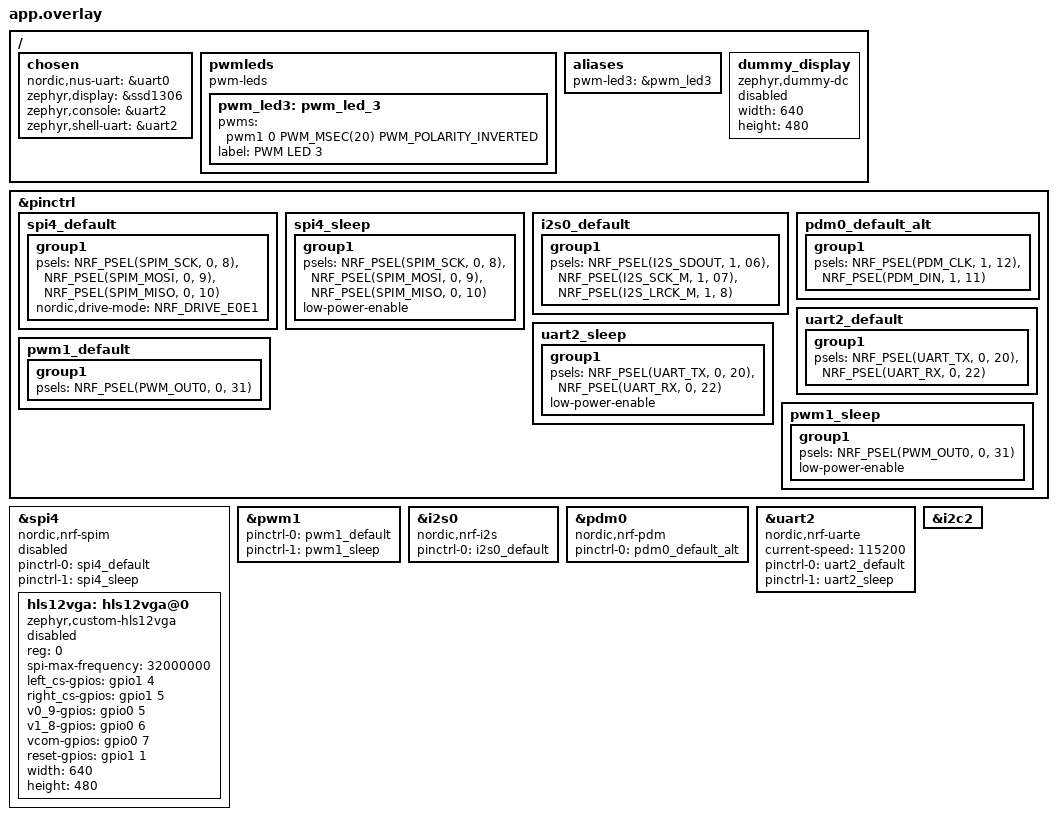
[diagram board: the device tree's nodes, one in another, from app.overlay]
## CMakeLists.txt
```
#
# Copyright (c) 2018 Nordic Semiconductor
#
# SPDX-License-Identifier: LicenseRef-Nordic-5-Clause

cmake_minimum_required(VERSION 3.20.0)

# Note: custom driver module registration enabled for HLS12VGA integration
set(ZEPHYR_EXTRA_MODULES ${CMAKE_CURRENT_SOURCE_DIR}/custom_driver_module)

find_package(Zephyr REQUIRED HINTS $ENV{ZEPHYR_BASE})
project(nrf5340_ble_simulator)

# Add nanopb support for protobuf
list(APPEND CMAKE_MODULE_PATH ${ZEPHYR_BASE}/modules/nanopb)
include(nanopb)

# Custom driver module picked up via ZEPHYR_EXTRA_MODULES (module.yml)
add_subdirectory(src/mos_components/mos_pdm)
add_subdirectory(src/mos_components/mos_interrupt)
add_subdirectory(src/mos_driver)

target_sources(app PRIVATE
    src/main.c
    src/protobuf_handler.c
    src/mentra_ble_service.c
    src/pdm_audio_stream.c
    src/lvgl_demo.c
    src/display_manager.c
    src/BspLog/bsp_log.c
    src/bsp_log_control.c
    src/shell_log_control.c
    src/shell_display_control.c
    src/shell_gx8002_control.c
    src/mos_components/mos_sysport/src/bal_os.c
    src/mos_components/mos_lvgl_display/src/mos_lvgl_display.c
    src/mos_components/mos_lvgl_display/src/display_config.c
)

# Add protobuf sources when available
if(EXISTS ${CMAKE_CURRENT_SOURCE_DIR}/src/proto/mentraos_ble.pb.c)
  target_sources(app PRIVATE src/proto/mentraos_ble.pb.c)
  target_include_directories(app PRIVATE src/proto)
elseif(EXISTS ${CMAKE_CURRENT_SOURCE_DIR}/src/mentraos_ble.pb.c)
  target_sources(app PRIVATE src/mentraos_ble.pb.c)
endif()

target_include_directories(app PRIVATE
    src
    src/BspLog
    src/mos_components/mos_sysport/include
    src/mos_components/mos_lvgl_display/include
    custom_driver_module/drivers
)
```

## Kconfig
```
#
# Copyright (c) 2018 Nordic Semiconductor
#
# SPDX-License-Identifier: LicenseRef-Nordic-5-Clause
#

source "Kconfig.zephyr"

menu "Nordic UART BLE GATT service sample"

config BT_NUS_THREAD_STACK_SIZE
	int "Thread stack size"
	default 1024
	help
	  Stack size used in each of the two threads

config BT_NUS_UART_BUFFER_SIZE
	int "UART payload buffer element size"
	default 40
	help
	  Size of the payload buffer in each RX and TX FIFO element

config BT_NUS_SECURITY_ENABLED
	bool "Enable security"
	default y
	select BT_SMP
	help
	  "Enable BLE security for the UART service"

config BT_NUS_UART_RX_WAIT_TIME
	int "Timeout for UART RX complete event"
	default 50000
	help
	  Wait for RX complete event time in microseconds

config SETTINGS
	default y

config ZMS
	default y if (SOC_FLASH_NRF_RRAM || SOC_FLASH_NRF_MRAM)

config NVS
	default y if !(SOC_FLASH_NRF_RRAM || SOC_FLASH_NRF_MRAM)

endmenu

# Include custom driver module Kconfig (projector display)
rsource "custom_driver_module/Kconfig"
```

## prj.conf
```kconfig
#
# Copyright (c) 2018 Nordic Semiconductor
#
# SPDX-License-Identifier: LicenseRef-Nordic-5-Clause
#

# Enable the UART driver
CONFIG_UART_ASYNC_API=y
CONFIG_NRFX_UARTE0=y
CONFIG_SERIAL=y

CONFIG_GPIO=y

# High-Frequency Clock Configuration for SPI Performance
CONFIG_CLOCK_CONTROL=y
CONFIG_CLOCK_CONTROL_NRF=y
# Enable NRFX clock driver for 128MHz configuration
CONFIG_NRFX_CLOCK=y
# Enable high-frequency external crystal for better SPI timing
CONFIG_SYSTEM_CLOCK_NO_WAIT=y

# Make sure printk is printing to the UART console
CONFIG_CONSOLE=y
CONFIG_UART_CONSOLE=y

CONFIG_HEAP_MEM_POOL_SIZE=2048

# High-Frequency Clock Configuration for SPI Performance
CONFIG_CLOCK_CONTROL=y
CONFIG_CLOCK_CONTROL_NRF=y
# Enable high-frequency external crystal for better SPI timing
CONFIG_SYSTEM_CLOCK_NO_WAIT=y

CONFIG_BT=y
CONFIG_BT_PERIPHERAL=y
CONFIG_BT_DEVICE_NAME="NexSim"
CONFIG_BT_MAX_CONN=1
CONFIG_BT_MAX_PAIRED=1

# Enable BLE GATT
CONFIG_BT_GATT_SERVICE_CHANGED=y

# Enable advertising
CONFIG_BT_BROADCASTER=y
CONFIG_BT_EXT_ADV=n

# Increase buffer sizes for protobuf messages
CONFIG_BT_L2CAP_TX_MTU=247
CONFIG_BT_BUF_ACL_RX_SIZE=251
CONFIG_BT_BUF_ACL_TX_SIZE=251

# Enable bonding
CONFIG_BT_SETTINGS=y
CONFIG_FLASH=y
CONFIG_FLASH_PAGE_LAYOUT=y
CONFIG_FLASH_MAP=y

# Enable DK LED and Buttons library
CONFIG_DK_LIBRARY=y

# Enable PWM for LED brightness control
CONFIG_PWM=y
CONFIG_PWM_LOG_LEVEL_DBG=y

CONFIG_SYSTEM_WORKQUEUE_STACK_SIZE=2048

CONFIG_MAIN_STACK_SIZE=4096
# Config logger
CONFIG_LOG=y
CONFIG_USE_SEGGER_RTT=y
# CONFIG_LOG_BACKEND_RTT=y
CONFIG_LOG_BACKEND_UART=n

CONFIG_LOG_PRINTK=y
# CONFIG_LOG_DEFAULT_LEVEL=0
# Configure log filtering - ensure printk goes to console
CONFIG_LOG_RUNTIME_FILTERING=y

CONFIG_ASSERT=y

# Enable nanopb for protobuf support
CONFIG_NANOPB=y

# Display + LVGL Configuration - WORKING IMPLEMENTATION FROM PERIPHERAL_UART_NEXT
CONFIG_DISPLAY=y
CONFIG_DISPLAY_LOG_LEVEL_ERR=y
CONFIG_LVGL=y
CONFIG_LV_COLOR_DEPTH_1=y
CONFIG_LV_Z_MEM_POOL_SIZE=65536
CONFIG_LV_USE_LABEL=y
CONFIG_LV_USE_THEME_DEFAULT=y

# Enable LVGL for Zephyr
CONFIG_LV_Z_FLUSH_THREAD=y
CONFIG_LV_Z_FLUSH_THREAD_STACK_SIZE=4096

# LVGL Display Buffer Settings - MUCH LARGER for full screen updates
# CONFIG_LV_Z_FULL_REFRESH=y
CONFIG_LV_Z_VDB_SIZE=40
CONFIG_LV_Z_DOUBLE_VDB=y
CONFIG_LV_Z_VDB_CUSTOM_SECTION=n
# Remove dummy display - switching to A6N projector for testing
# CONFIG_DUMMY_DISPLAY=y

# Enable custom A6N Display Driver for projector testing  
CONFIG_CUSTOM_A6N=y

# SPI Support for Display with High-Frequency Optimization
CONFIG_SPI=y
# Enhanced SPI configuration for 32MHz operation
CONFIG_SPI_ASYNC=y

# LVGL Fonts - Keep minimal set to save FLASH memory
CONFIG_LV_FONT_MONTSERRAT_12=y
CONFIG_LV_FONT_MONTSERRAT_14=y
# Large display fonts disabled to save FLASH memory
# CONFIG_LV_FONT_MONTSERRAT_16=y  
# CONFIG_LV_FONT_MONTSERRAT_18=y
# CONFIG_LV_FONT_MONTSERRAT_24=y
CONFIG_LV_FONT_MONTSERRAT_30=y
CONFIG_LV_FONT_MONTSERRAT_48=y

# Unicode and Font support for Chinese characters - minimal set
CONFIG_LV_USE_FONT_COMPRESSED=y
CONFIG_LV_FONT_FMT_TXT_LARGE=y

# Enable extended ASCII and Unicode support
CONFIG_LV_TXT_ENC_UTF8=y

# Enable only essential Chinese CJK font (14px sufficient for SSD1306)
# CONFIG_LV_FONT_SIMSUN_14_CJK=y
# CONFIG_LV_FONT_SIMSUN_16_CJK=y  # Disabled to save ~70KB

# International fonts disabled to save memory
# CONFIG_LV_FONT_DEJAVU_16_PERSIAN_HEBREW=y  # Disabled to save ~20KB  
# CONFIG_LV_FONT_UNSCII_8=y                 # Disabled to save ~8KB
# CONFIG_LV_FONT_UNSCII_16=y                # Disabled to save ~15KB

# Power Management
CONFIG_PM_DEVICE=y

# PDM Audio Configuration for Microphone Input
CONFIG_AUDIO=y
CONFIG_AUDIO_DMIC=y
CONFIG_AUDIO_DMIC_NRFX_PDM=y

# LC3 Codec Configuration for Audio Streaming  
CONFIG_AUDIO_CODEC=y

# Math library for audio processing
CONFIG_NEWLIB_LIBC=y
CONFIG_FPU=y


CONFIG_CMSIS_DSP=y
CONFIG_SW_CODEC_LC3_T2_SOFTWARE=y
CONFIG_LC3_ENC_CHAN_MAX=2
CONFIG_LC3_DEC_CHAN_MAX=2

CONFIG_NRFX_I2S0=y
CONFIG_USER_STEREO_1RX_L_1RX_R=y
# CONFIG_USER_STEREO_2RX_L is not set
# CONFIG_USER_STEREO_2RX_LR is not set

CONFIG_BT_USER_PHY_UPDATE=y
CONFIG_BT_USER_DATA_LEN_UPDATE=y

# CONFIG_SEGGER_RTT_BUFFER_SIZE_UP=4096
CONFIG_LOG_BUFFER_SIZE=8192
CONFIG_LOG_MODE_IMMEDIATE=n 
CONFIG_LOG_MODE_DEFERRED=y



CONFIG_SSD1306=y
CONFIG_I2C=y
# Additional I2C and SSD1306 support
CONFIG_GPIO=y
CONFIG_DISPLAY_LOG_LEVEL_DBG=y

CONFIG_TFM_SECURE_UART=n
CONFIG_TFM_LOG_LEVEL_SILENCE=y

# CONFIG_LV_USE_SYSMON=y
# CONFIG_LV_USE_PERF_MONITOR=y
# CONFIG_LV_FONT_DEFAULT_MONTSERRAT_12=y
# CONFIG_LV_USE_PERF_MONITOR_LOG_MODE=y

CONFIG_SHELL=y
CONFIG_LOG_CMDS=y
CONFIG_SHELL_BACKEND_SERIAL=y
CONFIG_SHELL_BACKEND_RTT=y
CONFIG_SHELL_PROMPT_UART="nrf5340:~$ "
CONFIG_SHELL_PROMPT_RTT="nrf5340:~$ "
CONFIG_SHELL_CMD_BUFF_SIZE=256
CONFIG_SHELL_PRINTF_BUFF_SIZE=64
CONFIG_SHELL_BACKEND_SERIAL_TX_RING_BUFFER_SIZE=512
CONFIG_SHELL_STACK_SIZE=8192
CONFIG_SHELL_BACKEND_SERIAL_LOG_MESSAGE_QUEUE_SIZE=2048
CONFIG_I2C_SHELL=y
CONFIG_SENSOR_SHELL=y

CONFIG_REGULATOR=y
CONFIG_SENSOR=y
CONFIG_LED=y
CONFIG_NRF_FUEL_GAUGE=y
CONFIG_NRF_FUEL_GAUGE_VARIANT_SECONDARY_CELL=y
# CONFIG_LSM6DSV16X=y
# CONFIG_LIS2MDL=y
```

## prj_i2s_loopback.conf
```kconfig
# I2S Simple Loopback Configuration
# This configuration enables only what's needed for I2S loopback testing

# Enable I2S
CONFIG_I2S=n
# We'll use nrfx_i2s directly, so disable Zephyr I2S driver

# Enable nrfx drivers
CONFIG_NRFX=y
CONFIG_NRFX_I2S=y
CONFIG_NRFX_CLOCK=y

# Enable GPIO for LED status
CONFIG_GPIO=y

# Enable logging
CONFIG_LOG=y
CONFIG_LOG_DEFAULT_LEVEL=3
CONFIG_USE_SEGGER_RTT=y
CONFIG_LOG_BACKEND_RTT=y
CONFIG_LOG_BACKEND_UART=n

# Enable console for logging
CONFIG_CONSOLE=y
CONFIG_RTT_CONSOLE=y
CONFIG_UART_CONSOLE=n

# System configuration
CONFIG_MAIN_STACK_SIZE=4096
CONFIG_SYSTEM_WORKQUEUE_STACK_SIZE=2048

# Memory configuration
CONFIG_HEAP_MEM_POOL_SIZE=8192

# Enable device tree overlays
CONFIG_PINCTRL=y

# Disable unused subsystems to avoid conflicts
CONFIG_BT=n
CONFIG_USB_DEVICE_STACK=n
CONFIG_NETWORKING=n
CONFIG_WIFI=n

# Enable floating point for audio processing if needed
CONFIG_FPU=y
CONFIG_CBPRINTF_FP_SUPPORT=y
```

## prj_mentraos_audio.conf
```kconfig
# MentraOS Audio System Configuration
# Enables PDM microphone and I2S audio output for complete audio pipeline

# Core system configuration
CONFIG_MAIN_STACK_SIZE=4096
CONFIG_SYSTEM_WORKQUEUE_STACK_SIZE=2048

# Audio subsystem
CONFIG_AUDIO=y

# I2S Audio Output Driver
CONFIG_I2S=y
CONFIG_NRFX_I2S=y
CONFIG_NRFX_I2S0=y

# PDM Microphone Driver  
CONFIG_PDM=y
CONFIG_NRFX_PDM=y
CONFIG_NRFX_PDM0=y

# GPIO for status indication
CONFIG_GPIO=y

# Audio clock configuration
CONFIG_CLOCK_CONTROL=y
CONFIG_NRFX_CLOCK=y
CONFIG_CLOCK_CONTROL_NRF_K32SRC_XTAL=y
CONFIG_CLOCK_CONTROL_NRF_K32SRC_500PPM=y

# High frequency clock for audio precision
CONFIG_CLOCK_CONTROL_NRF_HFCLK_DIV=1

# Audio clock (ACLK) for I2S and PDM
CONFIG_NRFX_CLOCK_LFCLK_RC=y

# Memory management for audio buffers
CONFIG_HEAP_MEM_POOL_SIZE=8192
CONFIG_SLAB_ALLOC=y

# Logging configuration for debugging
CONFIG_LOG=y
CONFIG_LOG_DEFAULT_LEVEL=3
CONFIG_LOG_BACKEND_UART=y
CONFIG_LOG_MODE_IMMEDIATE=y
CONFIG_CONSOLE=y
CONFIG_UART_CONSOLE=y
CONFIG_SERIAL=y

# Thread and synchronization
CONFIG_MULTITHREADING=y
CONFIG_NUM_COOP_PRIORITIES=10
CONFIG_NUM_PREEMPT_PRIORITIES=15
CONFIG_THREAD_NAME=y
CONFIG_THREAD_STACK_INFO=y

# Ring buffer for audio data flow
CONFIG_RING_BUFFER=y

# Math library for audio processing
CONFIG_NEWLIB_LIBC=y
CONFIG_NEWLIB_LIBC_FLOAT_PRINTF=y

# Power management (can be disabled for debug)
CONFIG_PM=n

# Networking disabled for audio focus
CONFIG_NETWORKING=n
CONFIG_BT=n

# USB for development (optional)
CONFIG_USB_DEVICE_STACK=y
CONFIG_USB_CDC_ACM=y

# Debug features
CONFIG_DEBUG=y
CONFIG_DEBUG_OPTIMIZATIONS=y
CONFIG_ASSERT=y
CONFIG_ASSERT_LEVEL=2

# Performance monitoring
CONFIG_TIMING_FUNCTIONS=y
CONFIG_THREAD_RUNTIME_STATS=y

# Pin control configuration
CONFIG_PINCTRL=y

# Device tree overlay
CONFIG_DTC_OVERLAY_FILE="mentraos_audio.overlay"
```

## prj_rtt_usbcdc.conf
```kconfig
# Combined Configuration: RTT Shell Backend + USB CDC Shell Backend
# Based on our RTT implementation + Cole's USB CDC implementation from dev-nexfirmware-a6n

# RTT Shell Backend Configuration - Real-time debugging via J-Link RTT
CONFIG_USE_SEGGER_RTT=y
CONFIG_SHELL_BACKEND_RTT=y
CONFIG_RTT_CONSOLE=y
CONFIG_SEGGER_RTT_MAX_NUM_UP_BUFFERS=3
CONFIG_SEGGER_RTT_MAX_NUM_DOWN_BUFFERS=3
CONFIG_SEGGER_RTT_BUFFER_SIZE_UP=1024
CONFIG_SEGGER_RTT_BUFFER_SIZE_DOWN=16
CONFIG_SEGGER_RTT_PRINTF_BUFFER_SIZE=64

# Shell Prompt Configuration - Unified MentraOS branding
CONFIG_SHELL_PROMPT_UART="MentraOS:~$ "
CONFIG_SHELL_PROMPT_RTT="MentraOS:~$ "

# USB CDC ACM Configuration for Shell and Log via USB
# Based on Cole's implementation from dev-nexfirmware-a6n branch
CONFIG_USB_DEVICE_STACK=y
CONFIG_USB_DEVICE_MANUFACTURER="Nordic Semiconductor"
CONFIG_USB_DEVICE_PRODUCT="nRF5340 BLE Simulator"
CONFIG_USB_DEVICE_VID=0x1915
CONFIG_USB_DEVICE_PID=0x530A
CONFIG_USB_CDC_ACM=y
CONFIG_UART_LINE_CTRL=y
CONFIG_USB_DEVICE_INITIALIZE_AT_BOOT=y
```

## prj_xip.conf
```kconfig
#
# XIP (eXecute In Place) Configuration for External SPI NOR Flash
# Based on prj.conf with XIP-specific additions
#

# Include base configuration
include prj.conf

# External Flash Support
CONFIG_NORDIC_QSPI_NOR=y
CONFIG_NORDIC_QSPI_NOR_FLASH_LAYOUT_PAGE_SIZE=4096
CONFIG_NORDIC_QSPI_NOR_STACK_WRITE_BUFFER_SIZE=16

# XIP (eXecute In Place) Configuration
CONFIG_XIP=y
CONFIG_MAIN_STACK_SIZE=4096
CONFIG_SYSTEM_WORKQUEUE_STACK_SIZE=4096

# Flash Configuration for XIP
CONFIG_FLASH=y
CONFIG_FLASH_PAGE_LAYOUT=y
CONFIG_FLASH_MAP=y
CONFIG_STREAM_FLASH=y

# LittleFS Configuration for External Flash
CONFIG_FILE_SYSTEM=y
CONFIG_FILE_SYSTEM_LITTLEFS=y
CONFIG_LITTLEFS_READ_SIZE=16
CONFIG_LITTLEFS_PROG_SIZE=16
CONFIG_LITTLEFS_CACHE_SIZE=64
CONFIG_LITTLEFS_LOOKAHEAD_SIZE=16
CONFIG_LITTLEFS_BLOCK_SIZE=4096
CONFIG_LITTLEFS_USE_MTIME=y

# Memory Management for XIP
CONFIG_HEAP_MEM_POOL_SIZE=8192
CONFIG_MAIN_STACK_SIZE=4096

# QSPI Performance Optimization
CONFIG_NORDIC_QSPI_NOR_FLASH_LAYOUT_PAGE_SIZE=4096
CONFIG_NORDIC_QSPI_NOR_STACK_WRITE_BUFFER_SIZE=16

# Enable XIP debugging
CONFIG_XIP_DEBUG=y
CONFIG_FLASH_LOG_LEVEL_DBG=y

# Bootloader Configuration for XIP
CONFIG_BOOTLOADER_MCUBOOT=y
CONFIG_IMG_MANAGER=y
CONFIG_IMG_ERASE_PROGRESSIVELY=y

# Partition Manager for XIP
CONFIG_PM_PARTITION_SIZE_MCUBOOT=0x10000
CONFIG_PM_PARTITION_SIZE_XIP=0x400000
CONFIG_PM_PARTITION_SIZE_LITTLEFS_STORAGE=0x400000
```

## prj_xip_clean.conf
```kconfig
# XIP Configuration Overlay for MX25R6435F 8MB NOR Flash  
# This file works with prj.conf to enable XIP functionality
# Usage: west build -- -DCONF_FILE="prj.conf;prj_xip_clean.conf"

# Core XIP Configuration
CONFIG_XIP=y

# Custom linker script for XIP support
CONFIG_HAVE_CUSTOM_LINKER_SCRIPT=y
CONFIG_CUSTOM_LINKER_SCRIPT="linker_arm_extxip.ld"

# External Flash Support via QSPI
CONFIG_FLASH=y
CONFIG_FLASH_MAP=y
CONFIG_FLASH_PAGE_LAYOUT=y
CONFIG_NORDIC_QSPI_NOR=y
CONFIG_NORDIC_QSPI_NOR_FLASH_LAYOUT_PAGE_SIZE=4096
CONFIG_NORDIC_QSPI_NOR_XIP=y

# File System Support
CONFIG_FILE_SYSTEM=y
CONFIG_FILE_SYSTEM_LITTLEFS=y

# Shell support for XIP testing  
CONFIG_SHELL=y
CONFIG_SHELL_BACKEND_SERIAL=y
CONFIG_SHELL_PROMPT_UART="xip:~$ "

# Enable additional logging for XIP debugging
CONFIG_LOG=y
CONFIG_LOG_DEFAULT_LEVEL=3
CONFIG_FLASH_LOG_LEVEL_DBG=y

# Memory optimization for XIP
CONFIG_MAIN_STACK_SIZE=4096
CONFIG_SYSTEM_WORKQUEUE_STACK_SIZE=4096

# Disable HLS12VGA driver for XIP testing to avoid undefined references
CONFIG_CUSTOM_HLS12VGA=n
```

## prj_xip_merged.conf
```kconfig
#
# Merged XIP Configuration for External SPI NOR Flash
# Based on prj.conf with XIP-specific additions
#

# Enable the UART driver
CONFIG_UART_ASYNC_API=y
CONFIG_NRFX_UARTE0=y
CONFIG_SERIAL=y

CONFIG_GPIO=y

# High-Frequency Clock Configuration for SPI Performance
CONFIG_CLOCK_CONTROL=y
CONFIG_CLOCK_CONTROL_NRF=y
# Enable NRFX clock driver for 128MHz configuration
CONFIG_NRFX_CLOCK=y
# Enable high-frequency external crystal for better SPI timing
CONFIG_SYSTEM_CLOCK_NO_WAIT=y

# Make sure printk is printing to the UART console
CONFIG_CONSOLE=y
CONFIG_UART_CONSOLE=y

CONFIG_HEAP_MEM_POOL_SIZE=8192

CONFIG_BT=y
CONFIG_BT_PERIPHERAL=y
CONFIG_BT_DEVICE_NAME="NexSim"
CONFIG_BT_MAX_CONN=1
CONFIG_BT_MAX_PAIRED=1

# Enable BLE GATT
CONFIG_BT_GATT_SERVICE_CHANGED=y

# Enable advertising
CONFIG_BT_BROADCASTER=y
CONFIG_BT_EXT_ADV=n

# Increase buffer sizes for protobuf messages
CONFIG_BT_L2CAP_TX_MTU=247
CONFIG_BT_BUF_ACL_RX_SIZE=251
CONFIG_BT_BUF_ACL_TX_SIZE=251

# Enable BT data length update
CONFIG_BT_DATA_LEN_UPDATE=y
CONFIG_BT_AUTO_DATA_LEN_UPDATE=y

# Enable BT PHY update
CONFIG_BT_PHY_UPDATE=y
CONFIG_BT_AUTO_PHY_UPDATE=y

# Enable DMIC/PDM for digital microphone input
CONFIG_AUDIO=y
CONFIG_AUDIO_DMIC=y

# Additional display/audio configurations from base prj.conf
CONFIG_DISPLAY=y
CONFIG_LVGL=y
CONFIG_LV_COLOR_DEPTH_1=y
CONFIG_LV_MEM_CUSTOM=y
CONFIG_LV_USE_LOG=y
CONFIG_LV_LOG_LEVEL_WARN=y
CONFIG_LV_THEME_BASIC=y
CONFIG_LV_USE_THEME_BASIC=y
CONFIG_LV_THEME_DEFAULT_DARK=y
CONFIG_LV_COLOR_CHROMA_KEY_HEX=0x00FF00

# Enable custom HLS12VGA Display Driver for projector testing  
CONFIG_CUSTOM_HLS12VGA=y

# SPI Support for Display with High-Frequency Optimization
CONFIG_SPI=y
CONFIG_SPI_ASYNC=y

# LVGL Fonts - Keep minimal set to save FLASH memory
CONFIG_LV_FONT_MONTSERRAT_12=y
CONFIG_LV_FONT_MONTSERRAT_14=y

# Unicode and Font support
CONFIG_LV_USE_FONT_COMPRESSED=y
CONFIG_LV_FONT_FMT_TXT_LARGE=y
CONFIG_LV_TXT_ENC_UTF8=y
CONFIG_LV_FONT_SIMSUN_14_CJK=y

# Power Management
CONFIG_PM_DEVICE=y

# PDM Audio Configuration for Microphone Input
CONFIG_AUDIO_DMIC_NRFX_PDM=y

# LC3 Codec Configuration for Audio Streaming  
CONFIG_AUDIO_CODEC=y

# Math library for audio processing
CONFIG_NEWLIB_LIBC=y
CONFIG_FPU=y
CONFIG_CMSIS_DSP=y
CONFIG_SW_CODEC_LC3_T2_SOFTWARE=y
CONFIG_LC3_ENC_CHAN_MAX=2
CONFIG_LC3_DEC_CHAN_MAX=2

CONFIG_NRFX_I2S0=y
CONFIG_USER_STEREO_1RX_L_1RX_R=y

CONFIG_BT_USER_PHY_UPDATE=y
CONFIG_BT_USER_DATA_LEN_UPDATE=y

# XIP-specific configurations
CONFIG_SEGGER_RTT_BUFFER_SIZE_UP=4096
CONFIG_CBPRINTF_FP_SUPPORT=y
CONFIG_MAIN_STACK_SIZE=4096
CONFIG_RTT_CONSOLE=y

# Logging configurations
CONFIG_LOG_BUFFER_SIZE=8192
CONFIG_LOG_MODE_IMMEDIATE=n 
CONFIG_LOG_MODE_DEFERRED=y

# Display configurations
CONFIG_SSD1306=y
CONFIG_I2C=y
CONFIG_DISPLAY_LOG_LEVEL_DBG=y

CONFIG_TFM_SECURE_UART=n
CONFIG_TFM_LOG_LEVEL_SILENCE=y

# Shell configurations - essential for XIP shell commands
CONFIG_SHELL=y
CONFIG_LOG_CMDS=y
CONFIG_SHELL_BACKEND_SERIAL=y
CONFIG_SHELL_PROMPT_UART="nrf5340:~$ "
CONFIG_SHELL_CMD_BUFF_SIZE=256
CONFIG_SHELL_PRINTF_BUFF_SIZE=64
CONFIG_SHELL_BACKEND_SERIAL_TX_RING_BUFFER_SIZE=4096
CONFIG_SHELL_STACK_SIZE=8192

# External Flash Support for XIP
CONFIG_NORDIC_QSPI_NOR=y
CONFIG_NORDIC_QSPI_NOR_FLASH_LAYOUT_PAGE_SIZE=4096
CONFIG_NORDIC_QSPI_NOR_STACK_WRITE_BUFFER_SIZE=16

# XIP (eXecute In Place) Configuration
CONFIG_XIP=y
CONFIG_SYSTEM_WORKQUEUE_STACK_SIZE=4096

# Flash Configuration for XIP
CONFIG_FLASH=y
CONFIG_FLASH_PAGE_LAYOUT=y
CONFIG_FLASH_MAP=y
CONFIG_STREAM_FLASH=y

# LittleFS Configuration for External Flash
CONFIG_FILE_SYSTEM=y
CONFIG_FILE_SYSTEM_LITTLEFS=y

# Enable QSPI Performance Optimization
CONFIG_NORDIC_QSPI_NOR_FLASH_LAYOUT_PAGE_SIZE=4096
CONFIG_NORDIC_QSPI_NOR_STACK_WRITE_BUFFER_SIZE=16

# Bootloader Configuration for XIP
CONFIG_BOOTLOADER_MCUBOOT=y
CONFIG_IMG_MANAGER=y
CONFIG_IMG_ERASE_PROGRESSIVELY=y
```

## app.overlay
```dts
/*
 * Copyright (c) 2022 Nordic Semiconductor ASA
 *
 * SPDX-License-Identifier: LicenseRef-Nordic-5-Clause
 */

/ {
	chosen {
		nordic,nus-uart = &uart0;
		/* Use HLS12VGA projector display */
		// zephyr,display = &hls12vga;
		zephyr,display = &ssd1306;
		/* UART2 for console/shell output on P0.20 (TX) and P0.22 (RX) */
		zephyr,console = &uart2;
		zephyr,shell-uart = &uart2;
	};
	
	pwmleds {
		compatible = "pwm-leds";
		
		/* PWM LED for brightness control on LED 3 (P0.31) */
		pwm_led3: pwm_led_3 {
			pwms = <&pwm1 0 PWM_MSEC(20) PWM_POLARITY_INVERTED>;
			label = "PWM LED 3";
		};
	};
	
	aliases {
		pwm-led3 = &pwm_led3;
	};

	/* Dummy display for testing (until projector driver properly integrated) */
	dummy_display: dummy_display {
		compatible = "zephyr,dummy-dc";
		width = <640>;
		height = <480>;
		status = "disabled";  // Disabled since we're using SSD1306
	};
};

&pinctrl {
	spi4_default: spi4_default {
		group1 {
			psels = <NRF_PSEL(SPIM_SCK,  0, 8)>,
			        <NRF_PSEL(SPIM_MOSI, 0, 9)>,
			        <NRF_PSEL(SPIM_MISO, 0, 10)>;
			nordic,drive-mode = <NRF_DRIVE_E0E1>;
		};
	};
	spi4_sleep: spi4_sleep {
		group1 {
			psels = <NRF_PSEL(SPIM_SCK,  0, 8)>,
			        <NRF_PSEL(SPIM_MOSI, 0, 9)>,
			        <NRF_PSEL(SPIM_MISO, 0, 10)>;
			low-power-enable;
		};
	};
	i2s0_default: i2s0_default {
		group1 {
			psels = <NRF_PSEL(I2S_SDOUT, 1, 06)>,
					<NRF_PSEL(I2S_SCK_M, 1, 07)>,
					<NRF_PSEL(I2S_LRCK_M, 1, 8)>;
			// <NRF_PSEL(I2S_SDIN, 0, 0)>;

		};
	};
	pdm0_default_alt: pdm0_default_alt {
		group1 {
			psels = <NRF_PSEL(PDM_CLK, 1, 12)>,
					<NRF_PSEL(PDM_DIN, 1, 11)>;

		};
	};

	// UART2 pinctrl configuration for P0.20 (TX) and P0.22 (RX)
	uart2_default: uart2_default {
		group1 {
			psels = <NRF_PSEL(UART_TX, 0, 20)>,
					<NRF_PSEL(UART_RX, 0, 22)>;
		};
	};
	uart2_sleep: uart2_sleep {
		group1 {
			psels = <NRF_PSEL(UART_TX, 0, 20)>,
					<NRF_PSEL(UART_RX, 0, 22)>;
			low-power-enable;
		};
	};

	// I2C2 pinctrl moved to board overlay
};

&spi4 {
	compatible = "nordic,nrf-spim";
	status = "disabled";
	pinctrl-0 = <&spi4_default>;
	pinctrl-1 = <&spi4_sleep>;
	pinctrl-names = "default", "sleep";

	hls12vga: hls12vga@0 {
		compatible = "zephyr,custom-hls12vga";
		reg = <0>;
		status = "disabled";
		spi-max-frequency = <32000000>;

		left_cs-gpios  = <&gpio1 4 GPIO_ACTIVE_HIGH>;
		right_cs-gpios = <&gpio1 5 GPIO_ACTIVE_HIGH>;
		v0_9-gpios     = <&gpio0 5 GPIO_ACTIVE_HIGH>;
		v1_8-gpios     = <&gpio0 6 GPIO_ACTIVE_HIGH>;
		vcom-gpios     = <&gpio0 7 GPIO_ACTIVE_HIGH>;
		reset-gpios    = <&gpio1 1 GPIO_ACTIVE_HIGH>;
		width = <640>;
		height = <480>;
	};
};

&pinctrl {
	pwm1_default: pwm1_default {
		group1 {
			psels = <NRF_PSEL(PWM_OUT0, 0, 31)>;
		};
	};

	pwm1_sleep: pwm1_sleep {
		group1 {
			psels = <NRF_PSEL(PWM_OUT0, 0, 31)>;
			low-power-enable;
		};
	};
};

&pwm1 {
	status = "okay";
	pinctrl-0 = <&pwm1_default>;
	pinctrl-1 = <&pwm1_sleep>;
	pinctrl-names = "default", "sleep";
};

&i2s0 {
	compatible = "nordic,nrf-i2s";
	status = "okay";
	pinctrl-0 = <&i2s0_default>;
	pinctrl-names = "default";
	// clock-source = "ACLK";
};

dmic_dev: &pdm0 {
	status = "okay";
	compatible = "nordic,nrf-pdm";
	pinctrl-0 = <&pdm0_default_alt>;
	pinctrl-names = "default";
	// clock-source = "ACLK";
};

// Enable UART2 for console/shell on P0.20 (TX) and P0.22 (RX)
&uart2 {
	compatible = "nordic,nrf-uarte";
	status = "okay";
	current-speed = <115200>;
	pinctrl-0 = <&uart2_default>;
	pinctrl-1 = <&uart2_sleep>;
	pinctrl-names = "default", "sleep";
};

&i2c2 {
    // SSD1306 configuration moved to board overlay
};
```

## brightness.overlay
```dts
/*
 * Copyright (c) 2024 Mentra
 *
 * SPDX-License-Identifier: Apache-2.0
 */

/ {
	pwmleds {
		compatible = "pwm-leds";
		
		/* PWM LED for brightness control on LED 3 (P0.31) */
		pwm_led3: pwm_led_3 {
			pwms = <&pwm1 0 PWM_MSEC(20) PWM_POLARITY_INVERTED>;
			label = "PWM LED 3";
		};
	};
	
	aliases {
		pwm-led3 = &pwm_led3;
	};
};

&pinctrl {
	pwm1_default: pwm1_default {
		group1 {
			psels = <NRF_PSEL(PWM_OUT0, 0, 31)>;
		};
	};

	pwm1_sleep: pwm1_sleep {
		group1 {
			psels = <NRF_PSEL(PWM_OUT0, 0, 31)>;
			low-power-enable;
		};
	};
};

&pwm1 {
	status = "okay";
	pinctrl-0 = <&pwm1_default>;
	pinctrl-1 = <&pwm1_sleep>;
	pinctrl-names = "default", "sleep";
};
```

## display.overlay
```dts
/*
 * Simplified Display Configuration for LVGL Testing
 * Uses dummy display driver to test LVGL functionality
 */

/ {
	chosen {
		zephyr,display = &dummy_display;
	};

	/* Dummy display device for LVGL testing */
	dummy_display: dummy_display {
		compatible = "zephyr,dummy-display";
		status = "okay";
		width = <640>;
		height = <480>;
		refresh-time-ms = <16>;  /* ~60 FPS */
	};
};
```

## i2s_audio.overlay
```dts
/**
 * I2S Audio Output Device Tree Overlay
 * 
 * Configures I2S peripheral for audio output on nRF5340DK
 * 
 * Pin Mapping:
 * - P1.06: I2S_LRCK (Left/Right Clock)
 * - P1.07: I2S_BCLK (Bit Clock)  
 * - P1.08: I2S_SDIN (Serial Data Input to DAC)
 * 
 * Audio Configuration:
 * - Sample Rate: 16kHz
 * - Channels: Stereo (2)
 * - Bit Depth: 16-bit
 * - Frame Duration: 10ms
 */

&pinctrl {
	i2s0_default: i2s0_default {
		group1 {
			/* I2S Clock signals */
			psels = <NRF_PSEL(I2S_LRCK, 1, 6)>,   /* P1.06 - Left/Right Clock */
			        <NRF_PSEL(I2S_BCLK, 1, 7)>,   /* P1.07 - Bit Clock */
			        <NRF_PSEL(I2S_SDIN, 1, 8)>;   /* P1.08 - Serial Data Input */
		};
	};

	i2s0_sleep: i2s0_sleep {
		group1 {
			psels = <NRF_PSEL(I2S_LRCK, 1, 6)>,
			        <NRF_PSEL(I2S_BCLK, 1, 7)>,
			        <NRF_PSEL(I2S_SDIN, 1, 8)>;
			low-power-enable;
		};
	};
};

&i2s0 {
	status = "okay";
	pinctrl-0 = <&i2s0_default>;
	pinctrl-1 = <&i2s0_sleep>;
	pinctrl-names = "default", "sleep";
	
	/* I2S Master Configuration */
	clock-source = "HFCLK";  /* High frequency clock for precision */
	
	/* Audio format configuration */
	master;                  /* nRF5340 is I2S master */
};
```

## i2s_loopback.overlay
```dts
/*
 * I2S Simple Loopback Device Tree Overlay
 * Configures I2S pins for nRF5340DK
 */

&pinctrl {
    i2s0_default: i2s0_default {
        group1 {
            psels = <NRF_PSEL(I2S_SCK_M, 1, 7)>,    /* P1.07 - BCLK */
                    <NRF_PSEL(I2S_LRCK_M, 1, 6)>,   /* P1.06 - LRCK */
                    <NRF_PSEL(I2S_SDOUT, 1, 8)>;    /* P1.08 - SDOUT */
        };
        group2 {
            psels = <NRF_PSEL(I2S_SDIN, 1, 9)>;     /* P1.09 - SDIN */
            bias-pull-up;
        };
    };

    i2s0_sleep: i2s0_sleep {
        group1 {
            psels = <NRF_PSEL(I2S_SCK_M, 1, 7)>,
                    <NRF_PSEL(I2S_LRCK_M, 1, 6)>,
                    <NRF_PSEL(I2S_SDOUT, 1, 8)>,
                    <NRF_PSEL(I2S_SDIN, 1, 9)>;
            low-power-enable;
        };
    };
};

&i2s0 {
    status = "disabled";  /* Disable Zephyr I2S driver to avoid conflicts */
};

/* Enable HFCLKAUDIO for audio applications */
&clock {
    hfclkaudio-frequency = <12288000>;  /* 12.288 MHz for audio */
};
```

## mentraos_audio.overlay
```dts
/**
 * @file mentraos_audio.overlay
 * @brief MentraOS Audio System Device Tree Overlay
 * 
 * Configures nRF5340 for complete audio pipeline:
 * - PDM microphone input (P1.11/P1.12)
 * - I2S audio output for MAX98357A (P1.06/P1.07/P1.08)
 * 
 * Based on actual MentraOS configuration from:
 * /Users/loayyari/Documents/Github/MentraOS_TESTS/mcu_client/nrf5340/mentraos_nrf5340/app.overlay
 * 
 * Hardware Setup:
 * MAX98357A I2S Audio Amplifier:
 *   - P1.06 → LRC (Left/Right Clock)
 *   - P1.07 → BCLK (Bit Clock)  
 *   - P1.08 → DIN (Audio Data Input)
 *   - VDD → 3.3V
 *   - GND → Ground
 * 
 * PDM Microphone:
 *   - P1.12 → CLK (PDM Clock)
 *   - P1.11 → DAT (PDM Data)
 *   - VDD → 3.3V
 *   - GND → Ground
 */

/ {
	chosen {
		// Use UART for logging output
		zephyr,console = &uart0;
		zephyr,shell-uart = &uart0;
	};
	
	aliases {
		// Define audio device aliases
		audio-i2s = &i2s0;
		audio-pdm = &pdm0;
	};
};

// Add audio clock support
&clock {
	hfclkaudio-frequency = <12288000>;
};

&pinctrl {
	// I2S pin configuration (matching MentraOS)
	i2s0_default: i2s0_default {
		group1 {
			psels = <NRF_PSEL(I2S_SDOUT, 1, 6)>,    // P1.06 - Serial Data Output to MAX98357A DIN
			        <NRF_PSEL(I2S_SCK_M, 1, 7)>,    // P1.07 - Serial Clock Master to MAX98357A BCLK
			        <NRF_PSEL(I2S_LRCK_M, 1, 8)>;   // P1.08 - LR Clock Master to MAX98357A LRC
		};
	};

	i2s0_sleep: i2s0_sleep {
		group1 {
			psels = <NRF_PSEL(I2S_SDOUT, 1, 6)>,
			        <NRF_PSEL(I2S_SCK_M, 1, 7)>,
			        <NRF_PSEL(I2S_LRCK_M, 1, 8)>;
			low-power-enable;
		};
	};

	// PDM pin configuration (matching MentraOS)
	pdm0_default_alt: pdm0_default_alt {
		group1 {
			psels = <NRF_PSEL(PDM_CLK, 1, 12)>,    // P1.12 - PDM Clock
			        <NRF_PSEL(PDM_DIN, 1, 11)>;    // P1.11 - PDM Data Input
		};
	};

	pdm0_sleep: pdm0_sleep {
		group1 {
			psels = <NRF_PSEL(PDM_CLK, 1, 12)>,
			        <NRF_PSEL(PDM_DIN, 1, 11)>;
			low-power-enable;
		};
	};
};

// I2S Audio Output Configuration (for MAX98357A)
&i2s0 {
	compatible = "nordic,nrf-i2s";
	status = "okay";
	pinctrl-0 = <&i2s0_default>;
	pinctrl-1 = <&i2s0_sleep>;
	pinctrl-names = "default", "sleep";
	
	// Audio clock configuration (matching MentraOS)
	clock-source = "ACLK";  // Use Audio Clock for precision timing
};

// PDM Microphone Configuration
&pdm0 {
	compatible = "nordic,nrf-pdm";
	status = "okay";
	pinctrl-0 = <&pdm0_default_alt>;
	pinctrl-1 = <&pdm0_sleep>;
	pinctrl-names = "default", "sleep";
	
	// PDM clock configuration - using ACLK for precision
	clock-source = "ACLK";
};

// UART Configuration for logging
&uart0 {
	status = "okay";
	current-speed = <115200>;
	pinctrl-0 = <&uart0_default>;
	pinctrl-1 = <&uart0_sleep>;
	pinctrl-names = "default", "sleep";
};

// GPIO Configuration (for status LED)
&gpio0 {
	status = "okay";
	sense-edge-mask = <0xffffffff>;
};

&gpio1 {
	status = "okay";
	sense-edge-mask = <0xffffffff>;
};

// Disable unused peripherals to save power
&uart1 {
	status = "disabled";
};

&spi0 {
	status = "disabled";
};

&spi1 {
	status = "disabled";
};

&spi2 {
	status = "disabled";
};

&i2c0 {
	status = "disabled";
};

&i2c1 {
	status = "disabled";
};

&pwm0 {
	status = "disabled";
};

&pwm1 {
	status = "disabled";
};

&pwm2 {
	status = "disabled";
};

// Disable NFC to free up pins
&nfct {
	status = "disabled";
};

// Keep USB CDC for development
&zephyr_udc0 {
	status = "okay";
};
```

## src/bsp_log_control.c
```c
/*
 * BSP Log Runtime Control
 * Provides runtime control over BSP logging levels
 */

#include "BspLog/bsp_log.h"
#include <zephyr/kernel.h>

// Runtime BSP log level control
// Default to level 0 (DISABLED) since BSP logs should have been migrated to Zephyr logging
int bsp_log_runtime_level = 0;

// Initialize BSP logging system
void bsp_log_init(void)
{
    // Set initial log level to disabled since BSP logging migration should be complete
    bsp_log_runtime_level = 0;
}

// Runtime level control functions
void bsp_log_set_level(int level)
{
    if (level >= 0 && level <= 5) {
        bsp_log_runtime_level = level;
    }
}

int bsp_log_get_level(void)
{
    return bsp_log_runtime_level;
}
```

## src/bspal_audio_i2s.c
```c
/*
 * @Author       : Cole
 * @Date         : 2025-08-05 18:00:04
 * @LastEditTime : 2025-08-18 09:41:37
 * @FilePath     : bspal_audio_i2s.c
 * @Description  :
 *
 *  Copyright (c) MentraOS Contributors 2025
 *  SPDX-License-Identifier: Apache-2.0
 */

#include "bspal_audio_i2s.h"

#include <nrfx_clock.h>
#include <nrfx_i2s.h>
#include <zephyr/device.h>
#include <zephyr/drivers/pinctrl.h>
#include <zephyr/kernel.h>

#include "BspLog/bsp_log.h"

#define I2S_NL DT_NODELABEL(i2s0)

#define TAG "BSPAL_I2S"
enum audio_i2s_state
{
    AUDIO_I2S_STATE_UNINIT,
    AUDIO_I2S_STATE_IDLE,
    AUDIO_I2S_STATE_STARTED,
};

static enum audio_i2s_state state = AUDIO_I2S_STATE_UNINIT;

PINCTRL_DT_DEFINE(I2S_NL);  // I2S0 pins

static nrfx_i2s_t i2s_inst = {
    .p_reg = NRF_I2S0,
    .drv_inst_idx = 0,
};
static uint32_t i2s_rx_req_buffer[2][PDM_PCM_REQ_BUFFER_SIZE];
static uint32_t i2s_tx_req_buffer[2][PDM_PCM_REQ_BUFFER_SIZE];

static nrfx_i2s_config_t cfg = {
    /* Pins are configured by pinctrl. */
    .skip_gpio_cfg = true,
    .skip_psel_cfg = true,
    .irq_priority = DT_IRQ(I2S_NL, priority),
    .mode = NRF_I2S_MODE_MASTER,
    .format = NRF_I2S_FORMAT_I2S,
    .alignment = NRF_I2S_ALIGN_LEFT,
    .sample_width = NRF_I2S_SWIDTH_16BIT,
    .channels = NRF_I2S_CHANNELS_STEREO,
    .enable_bypass = false,

    .clksrc    = NRF_I2S_CLKSRC_ACLK,    // Use audio clock
    .mck_setup = NRF_I2S_MCK_32MDIV8,    // For ACLK = ACLK/8 = 12.288M/8 = 1.536 MHz
    .ratio     = NRF_I2S_RATIO_96X,      // LRCK = 1.536M / 96 = 16 kHz precisely aligned
};

nrfx_i2s_buffers_t const i2s_req_buffer[2] = {
    {
        .p_rx_buffer = i2s_rx_req_buffer[0],
        .p_tx_buffer = i2s_tx_req_buffer[0],
        .buffer_size = PDM_PCM_REQ_BUFFER_SIZE,
    },

    {
        .p_rx_buffer = i2s_rx_req_buffer[1],
        .p_tx_buffer = i2s_tx_req_buffer[1],
        .buffer_size = PDM_PCM_REQ_BUFFER_SIZE,
    },
};

static uint32_t *volatile mp_block_to_fill = NULL;

static void i2s_buffer_req_evt_handle(nrfx_i2s_buffers_t const *p_released, uint32_t status)
{
    uint32_t err_code;
    if (!(status & NRFX_I2S_STATUS_NEXT_BUFFERS_NEEDED))  // If no next buffers 
    {
        BSP_LOGE(TAG, "i2s_buffer_req_evt_handle: No next buffers needed, status = %lu", status);
        return;
    }
    // p_released->p_rx_buffer is the completed buffer, can be released or used to fill next frame
    if (p_released->p_rx_buffer == NULL)
    {
        err_code = nrfx_i2s_next_buffers_set(&i2s_inst, &i2s_req_buffer[1]);
        mp_block_to_fill = i2s_tx_req_buffer[1];
    }
    else
    {
        err_code = nrfx_i2s_next_buffers_set(&i2s_inst, p_released);
        mp_block_to_fill = (uint32_t *)p_released->p_tx_buffer;
    }
}

void audio_i2s_start(void)
{
    __ASSERT_NO_MSG(state == AUDIO_I2S_STATE_IDLE);
    nrfx_err_t ret;
    /* Buffer size in 32-bit words */
    ret = nrfx_i2s_start(&i2s_inst, &i2s_req_buffer[0], 0);
    __ASSERT_NO_MSG(ret == NRFX_SUCCESS);

    state = AUDIO_I2S_STATE_STARTED;
}

void audio_i2s_stop(void)
{
    __ASSERT_NO_MSG(state == AUDIO_I2S_STATE_STARTED);

    nrfx_i2s_stop(&i2s_inst);

    state = AUDIO_I2S_STATE_IDLE;
}

// Custom I2S IRQ handler
static void i2s_irq_handler(const void *arg)
{
    nrfx_i2s_irq_handler();
}

void audio_i2s_init(void)
{
    __ASSERT_NO_MSG(state == AUDIO_I2S_STATE_UNINIT);

    nrfx_err_t ret;

    nrfx_clock_hfclkaudio_config_set(HFCLKAUDIO_12_288_MHZ);

    NRF_CLOCK->TASKS_HFCLKAUDIOSTART = 1;

    /* Wait for ACLK to start */
    while (NRF_CLOCK->EVENTS_HFCLKAUDIOSTARTED == 0)
    {
        k_sleep(K_MSEC(1));
    }

    ret = pinctrl_apply_state(PINCTRL_DT_DEV_CONFIG_GET(I2S_NL), PINCTRL_STATE_DEFAULT);
    __ASSERT_NO_MSG(ret == 0);

    IRQ_CONNECT(DT_IRQN(I2S_NL), DT_IRQ(I2S_NL, priority), i2s_irq_handler, NULL, 0);
    irq_enable(DT_IRQN(I2S_NL));

    ret = nrfx_i2s_init(&i2s_inst, &cfg, i2s_buffer_req_evt_handle);
    __ASSERT_NO_MSG(ret == NRFX_SUCCESS);

    state = AUDIO_I2S_STATE_IDLE;
    BSP_LOGI(TAG, "Audio I2S initialized OK!!!");
}

void i2s_pcm_player(void *i2c_pcm_data, int16_t i2c_pcm_size, uint8_t i2s_pcm_ch)
{
    // Simple test tone player - fill both channels with same data
    int16_t *pcm_data = (int16_t *)i2c_pcm_data;
    
    if (mp_block_to_fill == NULL) {
        return; // No buffer ready
    }

    for (uint16_t i = 0; i < i2c_pcm_size; i++)
    {
        uint32_t *p_word = &mp_block_to_fill[i];
        ((uint16_t *)p_word)[0] = (uint16_t)pcm_data[i]; // Left channel
        ((uint16_t *)p_word)[1] = (uint16_t)pcm_data[i]; // Right channel
    }
}
```

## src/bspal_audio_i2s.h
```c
/*** 
 * @Author       : Cole
 * @Date         : 2025-08-15 17:43:14
 * @LastEditTime : 2025-08-16 16:16:00
 * @FilePath     : bspal_audio_i2s.h
 * @Description  : 
 * @
 * @ Copyright (c) MentraOS Contributors 2025 
 * @ SPDX-License-Identifier: Apache-2.0
 */
#ifndef _BSPAL_AUDIO_I2S_H_
#define _BSPAL_AUDIO_I2S_H_

#include <zephyr/kernel.h>
#include <stdint.h>

/**
 * Calculation:
 * FREQ_VALUE = 2^16 * ((12 * f_out / 32M) - 4)
 * f_out == 12.288
 * 39845.888 = 2^16 * ((12 * 12.288 / 32M) - 4)
 * 39846 = 0x9BA6
 */
#define HFCLKAUDIO_12_288_MHZ 0x9BA6
#define HFCLKAUDIO_12_165_MHZ 0x8FD8
#define HFCLKAUDIO_12_411_MHZ 0xA774

// PDM PCM buffer size: 16K 16bit 10ms = 160 samples
#define PDM_PCM_REQ_BUFFER_SIZE 160

/**
 * @brief Function to fill the I2S PCM data buffer.
 * This function is called to fill the I2S PCM data buffer with audio data.
 * It handles different configurations for stereo and mono audio playback.
 * @param i2c_pcm_data Pointer to the PCM data to be played.
 * @param i2c_pcm_size Size of the PCM data in samples.
 * @param i2s_pcm_ch Channel number for the I2S playback.
 *                   1 for left channel, 2 for right channel.
 */
void i2s_pcm_player(void *i2c_pcm_data, int16_t i2c_pcm_size, uint8_t i2s_pcm_ch);

/**
 * @brief Supply the buffers to be used in the next part of the I2S transfer
 *
 * @param tx_buf Pointer to the buffer with data to be sent
 * @param rx_buf Pointer to the buffer for received data
 */
void audio_i2s_set_next_buf(const uint8_t *tx_buf, uint32_t *rx_buf);

/**
 * @brief Start the continuous I2S transfer
 */
void audio_i2s_start(void);

/**
 * @brief Stop the continuous I2S transfer
 */
void audio_i2s_stop(void);

/**
 * @brief Initialize I2S module
 */
void audio_i2s_init(void);

#endif /* _BSPAL_AUDIO_I2S_H_ */
```

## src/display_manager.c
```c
/*
 * Copyright (c) 2024 Mentra
 *
 * SPDX-License-Identifier: Apache-2.0
 */

#include <zephyr/kernel.h>
#include <zephyr/logging/log.h>
#include <string.h>
#include <lvgl.h>

#include "display_manager.h"
#include "mos_lvgl_display.h"

LOG_MODULE_REGISTER(display_manager, LOG_LEVEL_DBG);

// Message queue for display commands
#define DISPLAY_QUEUE_SIZE 10
K_MSGQ_DEFINE(display_msgq, sizeof(display_msg_t), DISPLAY_QUEUE_SIZE, 4);

// Display thread configuration
#define DISPLAY_THREAD_STACK_SIZE 4096
#define DISPLAY_THREAD_PRIORITY 6

K_THREAD_STACK_DEFINE(display_stack_area, DISPLAY_THREAD_STACK_SIZE);
static struct k_thread display_thread_data;
static k_tid_t display_thread_id;

// Current display state
static bool display_enabled = false;
static lv_obj_t *current_text_label = NULL;
static lv_obj_t *current_scroll_container = NULL;

// Font mapping table - All English Montserrat fonts enabled
static const struct {
    uint16_t code;
    const lv_font_t *font;
} font_map[] = {
    {12, &lv_font_montserrat_12},
    {14, &lv_font_montserrat_14},
    // Note: 16,18,24 pt fonts may not be available in current build
    // Using 30pt and 48pt as they're commonly enabled
    {30, &lv_font_montserrat_30},
    {48, &lv_font_montserrat_48},
    {0, &lv_font_montserrat_14}  // Default font (14pt) - guaranteed available
};

// Public function to get font by size - used by LVGL display system
const lv_font_t *display_get_font_by_size(int size)
{
    // Search for exact size match
    for (int i = 0; i < ARRAY_SIZE(font_map) - 1; i++) {  // -1 to skip default entry
        if (font_map[i].code == size) {
            return font_map[i].font;
        }
    }
    
    // Return default font if size not found
    return &lv_font_montserrat_14;
}

static void display_thread_entry(void *arg1, void *arg2, void *arg3);
static void handle_static_text_message(const display_msg_t *msg);
static void handle_scrolling_text_message(const display_msg_t *msg);
static void handle_brightness_message(const display_msg_t *msg);

int display_manager_init(void)
{
    LOG_INF("🖥️  Initializing display manager");
    
    // Start LVGL display thread first
    lvgl_display_thread();
    
    // Give LVGL some time to initialize
    k_msleep(100);
    
    // Start our display manager thread
    display_thread_id = k_thread_create(&display_thread_data,
                                       display_stack_area,
                                       K_THREAD_STACK_SIZEOF(display_stack_area),
                                       display_thread_entry,
                                       NULL, NULL, NULL,
                                       DISPLAY_THREAD_PRIORITY,
                                       0, K_NO_WAIT);
    
    if (display_thread_id == NULL) {
        LOG_ERR("❌ Failed to create display manager thread");
        return -ENOMEM;
    }
    
    k_thread_name_set(display_thread_id, "display_mgr");
    
    LOG_INF("✅ Display manager initialized successfully");
    return 0;
}

int display_manager_enable(void)
{
    display_msg_t msg = {
        .type = DISPLAY_MSG_ENABLE
    };
    
    int ret = k_msgq_put(&display_msgq, &msg, K_NO_WAIT);
    if (ret != 0) {
        LOG_WRN("⚠️  Display queue full, dropping enable message");
        return ret;
    }
    
    LOG_INF("🖥️  Display enable command queued");
    return 0;
}

int display_manager_disable(void)
{
    display_msg_t msg = {
        .type = DISPLAY_MSG_DISABLE
    };
    
    int ret = k_msgq_put(&display_msgq, &msg, K_NO_WAIT);
    if (ret != 0) {
        LOG_WRN("⚠️  Display queue full, dropping disable message");
        return ret;
    }
    
    LOG_INF("🖥️  Display disable command queued");
    return 0;
}

int display_manager_clear(void)
{
    display_msg_t msg = {
        .type = DISPLAY_MSG_CLEAR
    };
    
    int ret = k_msgq_put(&display_msgq, &msg, K_NO_WAIT);
    if (ret != 0) {
        LOG_WRN("⚠️  Display queue full, dropping clear message");
        return ret;
    }
    
    LOG_INF("🖥️  Display clear command queued");
    return 0;
}

int display_manager_show_static_text(const mentraos_ble_DisplayText *display_text)
{
    if (!display_text) {
        LOG_ERR("❌ Invalid display text pointer");
        return -EINVAL;
    }
    
    display_msg_t msg = {
        .type = DISPLAY_MSG_STATIC_TEXT,
        .payload.static_text = {
            .x = display_text->x,
            .y = display_text->y,
            .color = display_text->color,
            .font_code = display_text->font_code,
            .size = display_text->size
        }
    };
    
    // Copy text safely
    strncpy(msg.payload.static_text.text, display_text->text, sizeof(msg.payload.static_text.text) - 1);
    msg.payload.static_text.text[sizeof(msg.payload.static_text.text) - 1] = '\0';
    
    int ret = k_msgq_put(&display_msgq, &msg, K_NO_WAIT);
    if (ret != 0) {
        LOG_WRN("⚠️  Display queue full, dropping static text message");
        return ret;
    }
    
    LOG_INF("📝 Static text display command queued: \"%s\"", msg.payload.static_text.text);
    return 0;
}

int display_manager_show_scrolling_text(const mentraos_ble_DisplayScrollingText *scrolling_text)
{
    if (!scrolling_text) {
        LOG_ERR("❌ Invalid scrolling text pointer");
        return -EINVAL;
    }
    
    display_msg_t msg = {
        .type = DISPLAY_MSG_SCROLLING_TEXT,
        .payload.scrolling_text = {
            .x = scrolling_text->x,
            .y = scrolling_text->y,
            .width = scrolling_text->width,
            .height = scrolling_text->height,
            .color = scrolling_text->color,
            .font_code = scrolling_text->font_code,
            .align = scrolling_text->align,
            .speed = scrolling_text->speed,
            .line_spacing = scrolling_text->line_spacing,
            .loop = scrolling_text->loop,
            .pause_ms = scrolling_text->pause_ms
        }
    };
    
    // Copy text safely
    strncpy(msg.payload.scrolling_text.text, scrolling_text->text, sizeof(msg.payload.scrolling_text.text) - 1);
    msg.payload.scrolling_text.text[sizeof(msg.payload.scrolling_text.text) - 1] = '\0';
    
    int ret = k_msgq_put(&display_msgq, &msg, K_NO_WAIT);
    if (ret != 0) {
        LOG_WRN("⚠️  Display queue full, dropping scrolling text message");
        return ret;
    }
    
    LOG_INF("📜 Scrolling text display command queued: \"%s\"", msg.payload.scrolling_text.text);
    return 0;
}

int display_manager_set_brightness(uint8_t brightness_level)
{
    display_msg_t msg = {
        .type = DISPLAY_MSG_BRIGHTNESS,
        .payload.brightness.level = brightness_level
    };
    
    int ret = k_msgq_put(&display_msgq, &msg, K_NO_WAIT);
    if (ret != 0) {
        LOG_WRN("⚠️  Display queue full, dropping brightness message");
        return ret;
    }
    
    LOG_INF("💡 Display brightness command queued: %u%%", brightness_level);
    return 0;
}

const lv_font_t *display_manager_map_font(uint16_t font_code)
{
    for (int i = 0; i < ARRAY_SIZE(font_map); i++) {
        if (font_map[i].code == font_code) {
            return font_map[i].font;
        }
    }
    
    // Return default font if not found
    LOG_WRN("⚠️  Font code %u not found, using default", font_code);
    return &lv_font_montserrat_14;  // Was 16, using 14 for memory
}

lv_color_t display_manager_convert_color(uint32_t rgb888_color)
{
    uint8_t r = (rgb888_color >> 16) & 0xFF;
    uint8_t g = (rgb888_color >> 8) & 0xFF;
    uint8_t b = rgb888_color & 0xFF;
    
    return lv_color_make(r, g, b);
}

static void display_thread_entry(void *arg1, void *arg2, void *arg3)
{
    ARG_UNUSED(arg1);
    ARG_UNUSED(arg2);
    ARG_UNUSED(arg3);
    
    LOG_INF("🖥️  Display manager thread started");
    
    // Wait for LVGL to be ready
    k_msleep(500);
    
    // Initialize display by default
    display_open();
    display_enabled = true;
    
    display_msg_t msg;
    
    while (1) {
        // Wait for display messages with 100ms timeout
        int ret = k_msgq_get(&display_msgq, &msg, K_MSEC(100));
        
        if (ret == 0) {
            // Process the message
            switch (msg.type) {
            case DISPLAY_MSG_ENABLE:
                if (!display_enabled) {
                    display_open();
                    display_enabled = true;
                    LOG_INF("🖥️  Display enabled");
                }
                break;
                
            case DISPLAY_MSG_DISABLE:
                if (display_enabled) {
                    display_close();
                    display_enabled = false;
                    LOG_INF("🖥️  Display disabled");
                }
                break;
                
            case DISPLAY_MSG_CLEAR:
                if (display_enabled) {
                    // Clear existing text elements
                    if (current_text_label) {
                        lv_obj_del(current_text_label);
                        current_text_label = NULL;
                    }
                    if (current_scroll_container) {
                        scroll_text_stop();
                        current_scroll_container = NULL;
                    }
                    LOG_INF("🖥️  Display cleared");
                }
                break;
                
            case DISPLAY_MSG_STATIC_TEXT:
                if (display_enabled) {
                    handle_static_text_message(&msg);
                }
                break;
                
            case DISPLAY_MSG_SCROLLING_TEXT:
                if (display_enabled) {
                    handle_scrolling_text_message(&msg);
                }
                break;
                
            case DISPLAY_MSG_BRIGHTNESS:
                handle_brightness_message(&msg);
                break;
                
            default:
                LOG_WRN("⚠️  Unknown display message type: %d", msg.type);
                break;
            }
        }
        
        // Small delay to prevent excessive CPU usage
        k_msleep(10);
    }
}

static void handle_static_text_message(const display_msg_t *msg)
{
    // Clear any existing text
    if (current_text_label) {
        lv_obj_del(current_text_label);
        current_text_label = NULL;
    }
    
    // Create new text label
    current_text_label = lv_label_create(lv_screen_active());
    if (!current_text_label) {
        LOG_ERR("❌ Failed to create text label");
        return;
    }
    
    // Set text content
    lv_label_set_text(current_text_label, msg->payload.static_text.text);
    
    // Set position
    lv_obj_set_pos(current_text_label, msg->payload.static_text.x, msg->payload.static_text.y);
    
    // Set font
    const lv_font_t *font = display_manager_map_font(msg->payload.static_text.font_code);
    lv_obj_set_style_text_font(current_text_label, font, LV_PART_MAIN);
    
    // Set color
    lv_color_t color = display_manager_convert_color(msg->payload.static_text.color);
    lv_obj_set_style_text_color(current_text_label, color, LV_PART_MAIN);
    
    LOG_INF("📝 Static text displayed: \"%s\" at (%d,%d)", 
            msg->payload.static_text.text,
            msg->payload.static_text.x,
            msg->payload.static_text.y);
}

static void handle_scrolling_text_message(const display_msg_t *msg)
{
    // Stop any existing scrolling text
    if (current_scroll_container) {
        scroll_text_stop();
        current_scroll_container = NULL;
    }
    
    // Calculate scroll time from speed
    // For now, use a fixed time or derive from speed parameter
    uint32_t scroll_time_ms = 3000; // 3 seconds default
    if (msg->payload.scrolling_text.speed > 0) {
        // Simple calculation: time based on speed (px/sec)
        scroll_time_ms = (msg->payload.scrolling_text.width * 1000) / msg->payload.scrolling_text.speed;
    }
    
    // Get font for scrolling text
    const lv_font_t *font = display_manager_map_font(msg->payload.scrolling_text.font_code);
    
    // Create scrolling text using existing function
    scroll_text_create(lv_screen_active(),
                      msg->payload.scrolling_text.x,
                      msg->payload.scrolling_text.y,
                      msg->payload.scrolling_text.width,
                      msg->payload.scrolling_text.height,
                      msg->payload.scrolling_text.text,
                      font,
                      scroll_time_ms);
    
    // Mark that we have active scrolling text
    current_scroll_container = (lv_obj_t *)1; // Non-null indicator
    
    LOG_INF("📜 Scrolling text displayed: \"%s\" at (%d,%d) size %dx%d", 
            msg->payload.scrolling_text.text,
            msg->payload.scrolling_text.x,
            msg->payload.scrolling_text.y,
            msg->payload.scrolling_text.width,
            msg->payload.scrolling_text.height);
}

static void handle_brightness_message(const display_msg_t *msg)
{
    // The brightness control is handled at the hardware level (PWM for LEDs)
    // For display brightness, we could potentially control backlight here
    // For now, just log the brightness change
    LOG_INF("💡 Display brightness request: %u%%", msg->payload.brightness.level);
    
    // TODO: Implement actual display brightness control if hardware supports it
}
```

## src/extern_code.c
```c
/*
 * @Author       : Cole
 * @Date         : 2025-04-24 23:29:30
 * @LastEditTime : 2025-10-09 10:44:33
 * @FilePath     : extern_code.c
 * @Description  : 
 * 
 *  Copyright (c) MentraOS Contributors 2025 
 *  SPDX-License-Identifier: Apache-2.0
 */
#include <zephyr/kernel.h>
#include <zephyr/sys/printk.h>
#include <zephyr/logging/log.h>

LOG_MODULE_REGISTER(ext_code, LOG_LEVEL_INF);

uint32_t var_ext_sram_data = 10U;

void function_in_extern_flash(void)
{
	LOG_INF("Address of %s %p", __func__, &function_in_extern_flash);
	LOG_INF("Address of var_ext_sram_data %p (value: %d)", (void *)&var_ext_sram_data, var_ext_sram_data);

}
void test_extern_flash(void)
{
	LOG_INF("Address of %s %p", __func__, &test_extern_flash);
}
```
